VERSION ""

NS_ :

BS_:

BU_: BCM VSP STRG MA EPS AV AVM AIRBAG IPDMer BRAKE ABS VCM

BO_ 3221225472 VECTOR__INDEPENDENT_SIG_MSG: 0 Vector__XXX
 SG_ Unknown_176_4 : 32|8@1+ (1,0) [0|0] "" Vector__XXX
 SG_ NewSignal_0024 : 32|8@1+ (1,0) [0|0] "" Vector__XXX
 SG_ Unknown_215_6 : 0|8@1+ (1,0) [0|0] "" Vector__XXX
 SG_ NewSignal_0047 : 0|8@1+ (1,0) [0|0] "" Vector__XXX
 SG_ BCM_RearRightDoorOpene111d : 1|1@1+ (1,0) [0|0] "" Vector__XXX
 SG_ NewSignal_0089 : 9|1@1+ (1,0) [0|0] "" Vector__XXX
 SG_ Unknown_55A_0 : 0|8@1+ (1,0) [0|0] "" Vector__XXX
 SG_ RawTemperature2 : 55|16@0+ (1,0) [0|0] "" Vector__XXX
 SG_ GIDStoClusterMaybe : 8|8@1+ (1,0) [0|0] "" Vector__XXX
 SG_ InverterVehicleSpeedSignal : 0|8@1+ (1,0) [0|0] "" Vector__XXX
 SG_ MotorVoltageSignal : 8|8@1+ (1,0) [0|0] "" Vector__XXX
 SG_ InverterVehicleSpeedSignal2 : 16|8@1+ (1,0) [0|0] "" Vector__XXX
 SG_ MotorVoltageSignal2 : 24|8@1+ (1,0) [0|0] "" Vector__XXX
 SG_ Unknown_551_5 : 40|8@1+ (1,0) [0|0] "" Vector__XXX
 SG_ Unknown_50A_0 : 0|8@1+ (1,0) [0|0] "" Vector__XXX
 SG_ Unknown_50A_1 : 8|8@1+ (1,0) [0|0] "" Vector__XXX
 SG_ Unknown_50D_2 : 16|8@1+ (1,0) [0|0] "" Vector__XXX
 SG_ Unknown_50D_5 : 40|8@1+ (1,0) [0|0] "" Vector__XXX
 SG_ Unknown_5B3_2 : 16|8@1+ (1,0) [0|0] "" Vector__XXX
 SG_ Unknown_5B3_3 : 24|8@1+ (1,0) [0|0] "" Vector__XXX
 SG_ Unknown_5B3_6 : 48|3@1+ (1,0) [0|0] "" Vector__XXX
 SG_ Unknown_510_1 : 8|8@1+ (1,0) [0|0] "" Vector__XXX
 SG_ Unknown_245_1 : 8|4@1+ (1,0) [0|0] "" Vector__XXX

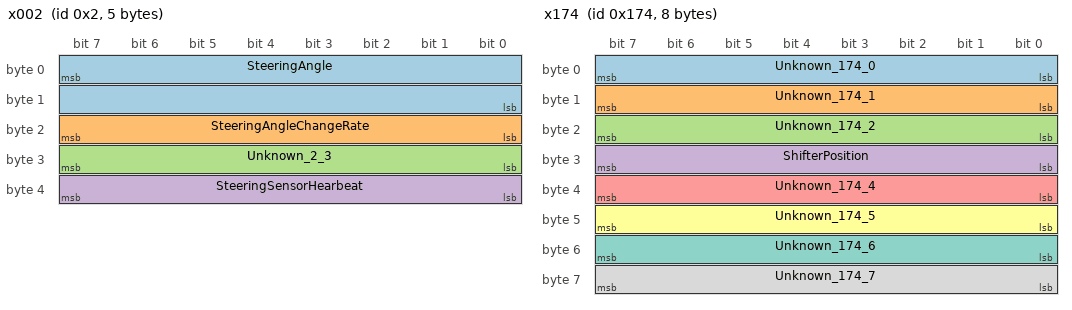
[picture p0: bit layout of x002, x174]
BO_ 2 x002: 5 STRG
 SG_ SteeringAngle : 7|16@0+ (1,0) [0|65535] "ddeg" Vector__XXX
 SG_ SteeringAngleChangeRate : 23|8@0+ (1,0) [0|255] "" Vector__XXX
 SG_ Unknown_2_3 : 31|8@0+ (1,0) [0|0] "" Vector__XXX
 SG_ SteeringSensorHearbeat : 39|8@0+ (1,0) [0|0] "" Vector__XXX

BO_ 42 x02A: 3 Vector__XXX
 SG_ Unknown_2A_0 : 0|8@1+ (1,0) [0|0] "" Vector__XXX
 SG_ Unknown_2A_1 : 8|8@1+ (1,0) [0|0] "" Vector__XXX
 SG_ Unknown_2A_2 : 16|8@1+ (1,0) [0|0] "" Vector__XXX

BO_ 304 x130: 3 ABS
 SG_ Unknown_130_0 : 0|8@1+ (1,0) [0|0] "" Vector__XXX
 SG_ BitmaskABS : 8|8@1+ (1,0) [0|0] "" Vector__XXX
 SG_ Unknown_130_1 : 16|8@1+ (1,0) [0|0] "" Vector__XXX

BO_ 372 x174: 8 VCM
 SG_ Unknown_174_0 : 0|8@1+ (1,0) [0|0] "" Vector__XXX
 SG_ Unknown_174_1 : 8|8@1+ (1,0) [0|0] "" Vector__XXX
 SG_ Unknown_174_2 : 16|8@1+ (1,0) [0|0] "" Vector__XXX
 SG_ ShifterPosition : 24|8@1+ (1,0) [0|0] "" Vector__XXX
 SG_ Unknown_174_4 : 32|8@1+ (1,0) [0|0] "" Vector__XXX
 SG_ Unknown_174_5 : 40|8@1+ (1,0) [0|0] "" Vector__XXX
 SG_ Unknown_174_6 : 48|8@1+ (1,0) [0|0] "" Vector__XXX
 SG_ Unknown_174_7 : 56|8@1+ (1,0) [0|0] "" Vector__XXX

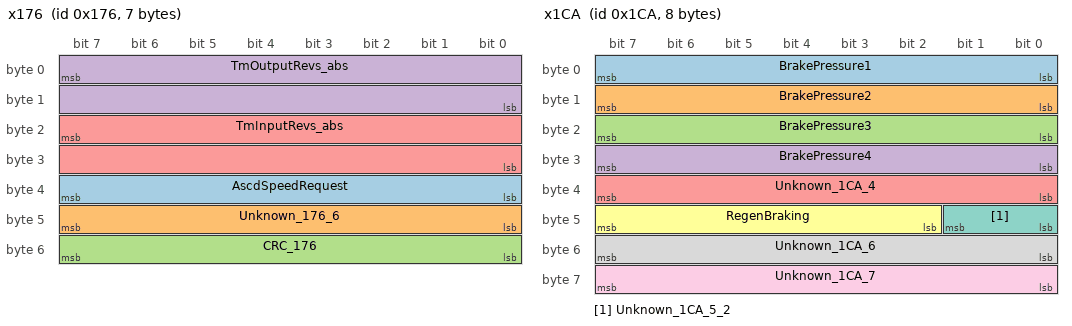
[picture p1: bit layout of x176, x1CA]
BO_ 374 x176: 7 VCM
 SG_ AscdSpeedRequest : 39|8@0+ (1,0) [0|250] "kmh" Vector__XXX
 SG_ Unknown_176_6 : 40|8@1+ (1,0) [0|0] "" Vector__XXX
 SG_ CRC_176 : 48|8@1+ (1,0) [0|0] "" Vector__XXX
 SG_ TmOutputRevs_abs : 7|16@0+ (1,0) [0|11000] "rpm" Vector__XXX
 SG_ TmInputRevs_abs : 23|16@0+ (1,0) [0|11000] "rpm" Vector__XXX

BO_ 384 x180_ECM_TorqueControl_RN1: 8 VCM
 SG_ Unknown_180_0 : 0|8@1+ (1,0) [0|0] "" Vector__XXX
 SG_ Unknown_180_1 : 8|8@1+ (1,0) [0|0] "" Vector__XXX
 SG_ MotorAmp : 23|12@0- (1,0) [0|0] "" Vector__XXX
 SG_ MotorAmpAlternative : 27|12@0- (1,0) [0|0] "" Vector__XXX
 SG_ ThrottlePosition : 40|8@1+ (0.5,0) [0|100] "%" Vector__XXX
 SG_ Unknown_180_5 : 48|8@1+ (1,0) [0|0] "" Vector__XXX
 SG_ Unknown_180_6 : 56|8@1+ (1,0) [0|0] "" Vector__XXX
 SG_ Unknown_180_7 : 0|8@1+ (1,0) [0|0] "" Vector__XXX

BO_ 458 x1CA: 8 BRAKE
 SG_ BrakePressure1 : 0|8@1+ (1,0) [0|0] "" Vector__XXX
 SG_ BrakePressure2 : 8|8@1+ (1,0) [0|0] "" Vector__XXX
 SG_ BrakePressure3 : 16|8@1+ (1,0) [0|0] "" Vector__XXX
 SG_ BrakePressure4 : 24|8@1+ (1,0) [0|0] "" Vector__XXX
 SG_ Unknown_1CA_4 : 32|8@1+ (1,0) [0|0] "" Vector__XXX
 SG_ RegenBraking : 42|6@1+ (1,0) [0|0] "" Vector__XXX
 SG_ Unknown_1CA_5_2 : 40|2@1+ (1,0) [0|0] "" Vector__XXX
 SG_ Unknown_1CA_6 : 48|8@1+ (1,0) [0|0] "" Vector__XXX
 SG_ Unknown_1CA_7 : 56|8@1+ (1,0) [0|0] "" Vector__XXX

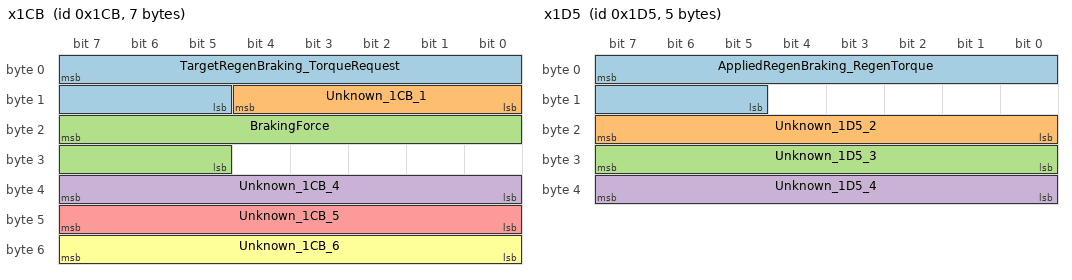
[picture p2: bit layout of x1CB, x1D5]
BO_ 459 x1CB: 7 Vector__XXX
 SG_ TargetRegenBraking_TorqueRequest : 7|11@0+ (1,0) [0|0] "Nm" Vector__XXX
 SG_ Unknown_1CB_1 : 8|5@1+ (1,0) [0|0] "" Vector__XXX
 SG_ BrakingForce : 23|11@0+ (1,0) [0|0] "N" Vector__XXX
 SG_ Unknown_1CB_4 : 32|8@1+ (1,0) [0|0] "" Vector__XXX
 SG_ Unknown_1CB_5 : 40|8@1+ (1,0) [0|0] "" Vector__XXX
 SG_ Unknown_1CB_6 : 48|8@1+ (1,0) [0|0] "" Vector__XXX

BO_ 469 x1D5: 5 VCM
 SG_ AppliedRegenBraking_RegenTorque : 7|11@0+ (1,0) [0|0] "Nm" Vector__XXX
 SG_ Unknown_1D5_2 : 16|8@1+ (1,0) [0|0] "" Vector__XXX
 SG_ Unknown_1D5_3 : 24|8@1+ (1,0) [0|0] "" Vector__XXX
 SG_ Unknown_1D5_4 : 32|8@1+ (1,0) [0|0] "" Vector__XXX

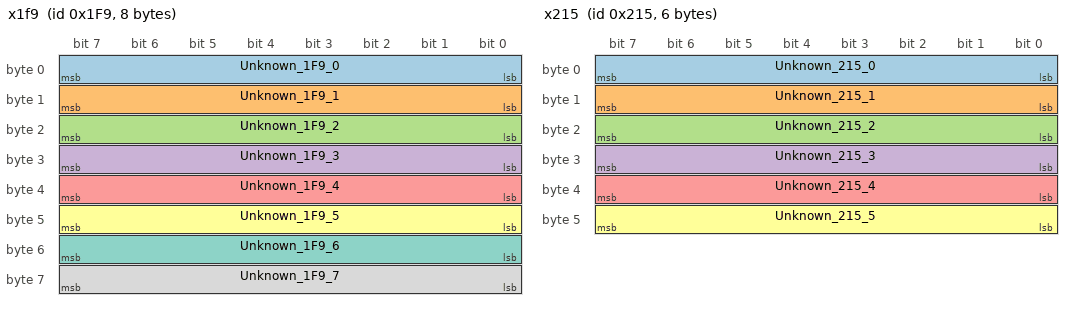
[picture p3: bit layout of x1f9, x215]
BO_ 505 x1f9: 8 Vector__XXX
 SG_ Unknown_1F9_0 : 0|8@1+ (1,0) [0|0] "" Vector__XXX
 SG_ Unknown_1F9_1 : 8|8@1+ (1,0) [0|0] "" Vector__XXX
 SG_ Unknown_1F9_2 : 16|8@1+ (1,0) [0|0] "" Vector__XXX
 SG_ Unknown_1F9_3 : 24|8@1+ (1,0) [0|0] "" Vector__XXX
 SG_ Unknown_1F9_4 : 32|8@1+ (1,0) [0|0] "" Vector__XXX
 SG_ Unknown_1F9_5 : 40|8@1+ (1,0) [0|0] "" Vector__XXX
 SG_ Unknown_1F9_6 : 48|8@1+ (1,0) [0|0] "" Vector__XXX
 SG_ Unknown_1F9_7 : 56|8@1+ (1,0) [0|0] "" Vector__XXX

BO_ 533 x215: 6 Vector__XXX
 SG_ Unknown_215_0 : 0|8@1+ (1,0) [0|0] "" Vector__XXX
 SG_ Unknown_215_1 : 8|8@1+ (1,0) [0|0] "" Vector__XXX
 SG_ Unknown_215_2 : 16|8@1+ (1,0) [0|0] "" Vector__XXX
 SG_ Unknown_215_3 : 24|8@1+ (1,0) [0|0] "" Vector__XXX
 SG_ Unknown_215_4 : 32|8@1+ (1,0) [0|0] "" Vector__XXX
 SG_ Unknown_215_5 : 40|8@1+ (1,0) [0|0] "" Vector__XXX

BO_ 534 x216: 2 Vector__XXX
 SG_ Unknown_216_0 : 0|8@1+ (1,0) [0|0] "" Vector__XXX
 SG_ Unknown_216_1 : 8|8@1+ (1,0) [0|0] "" Vector__XXX

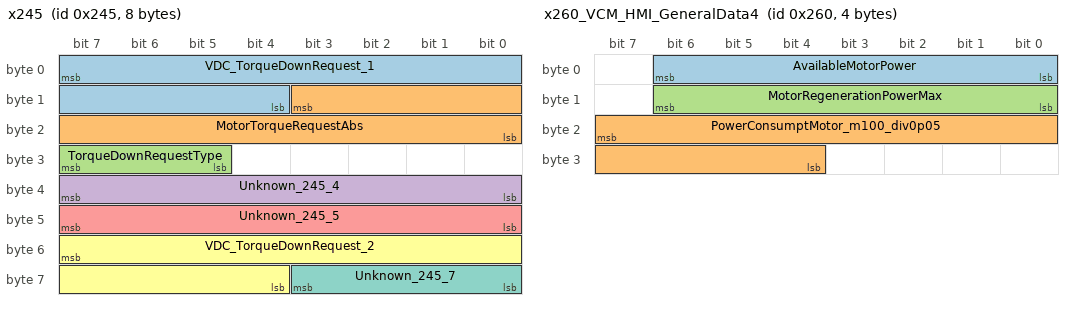
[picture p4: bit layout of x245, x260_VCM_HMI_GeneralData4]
BO_ 581 x245: 8 ABS
 SG_ VDC_TorqueDownRequest_1 : 7|12@0+ (2.5,0) [0|5115] "Nm" Vector__XXX
 SG_ MotorTorqueRequestAbs : 11|12@0+ (2.5,0) [0|5115] "Nm" Vector__XXX
 SG_ TorqueDownRequestType : 31|3@0+ (1,0) [0|0] "" Vector__XXX
 SG_ Unknown_245_4 : 32|8@1+ (1,0) [0|0] "" Vector__XXX
 SG_ Unknown_245_5 : 40|8@1+ (1,0) [0|0] "" Vector__XXX
 SG_ VDC_TorqueDownRequest_2 : 55|12@0+ (2.5,0) [0|5115] "Nm" Vector__XXX
 SG_ Unknown_245_7 : 56|4@1+ (1,0) [0|0] "" Vector__XXX

BO_ 608 x260_VCM_HMI_GeneralData4: 4 VCM
 SG_ AvailableMotorPower : 6|7@0+ (1,0) [0|90] "kW" Vector__XXX
 SG_ PowerConsumptMotor_m100_div0p05 : 23|12@0+ (0.05,-100) [-50|90] "kW" Vector__XXX
 SG_ MotorRegenerationPowerMax : 14|7@0+ (1,0) [0|50] "kW" Vector__XXX

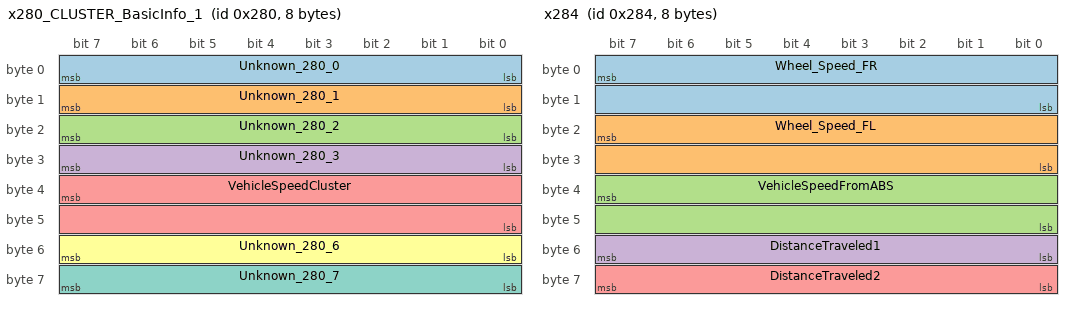
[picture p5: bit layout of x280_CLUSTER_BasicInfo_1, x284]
BO_ 640 x280_CLUSTER_BasicInfo_1: 8 MA
 SG_ Unknown_280_0 : 0|8@1+ (1,0) [0|0] "" Vector__XXX
 SG_ Unknown_280_1 : 8|8@1+ (1,0) [0|0] "" Vector__XXX
 SG_ Unknown_280_2 : 16|8@1+ (1,0) [0|0] "" Vector__XXX
 SG_ Unknown_280_3 : 24|8@1+ (1,0) [0|0] "" Vector__XXX
 SG_ VehicleSpeedCluster : 39|16@0+ (0.01,0) [0|0] "km/h" Vector__XXX
 SG_ Unknown_280_6 : 48|8@1+ (1,0) [0|0] "" Vector__XXX
 SG_ Unknown_280_7 : 56|8@1+ (1,0) [0|0] "" Vector__XXX

BO_ 644 x284: 8 ABS
 SG_ Wheel_Speed_FR : 7|16@0+ (0.005,0) [0|327] "km/h" Vector__XXX
 SG_ Wheel_Speed_FL : 23|16@0+ (0.005,0) [0|327] "km/h" Vector__XXX
 SG_ VehicleSpeedFromABS : 39|16@0+ (0.01,0) [0|0] "" Vector__XXX
 SG_ DistanceTraveled1 : 48|8@1+ (1,0) [0|0] "" Vector__XXX
 SG_ DistanceTraveled2 : 56|8@1+ (1,0) [0|0] "" Vector__XXX

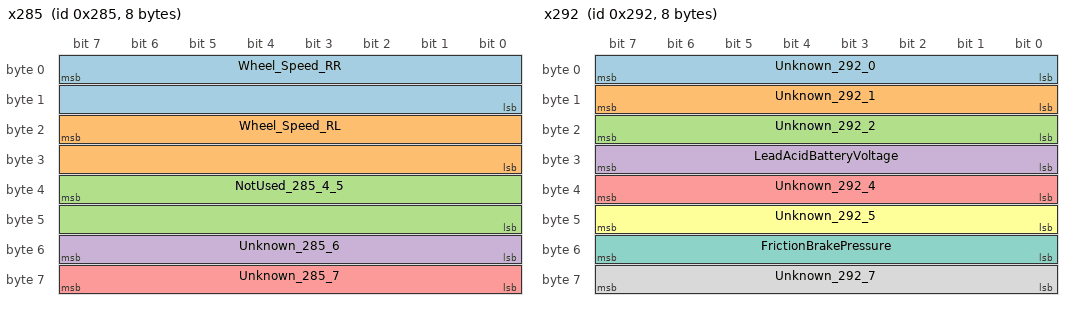
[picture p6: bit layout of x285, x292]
BO_ 645 x285: 8 ABS
 SG_ Wheel_Speed_RR : 7|16@0+ (0.005,0) [0|327] "km/h" Vector__XXX
 SG_ Wheel_Speed_RL : 23|16@0+ (0.005,0) [0|327] "km/h" Vector__XXX
 SG_ NotUsed_285_4_5 : 39|16@0+ (1,0) [0|0] "" Vector__XXX
 SG_ Unknown_285_6 : 48|8@1+ (1,0) [0|0] "" Vector__XXX
 SG_ Unknown_285_7 : 56|8@1+ (1,0) [0|0] "" Vector__XXX

BO_ 658 x292: 8 ABS
 SG_ Unknown_292_0 : 0|8@1+ (1,0) [0|0] "" Vector__XXX
 SG_ Unknown_292_1 : 8|8@1+ (1,0) [0|0] "" Vector__XXX
 SG_ Unknown_292_2 : 16|8@1+ (1,0) [0|0] "" Vector__XXX
 SG_ LeadAcidBatteryVoltage : 24|8@1+ (1,0) [0|150] "dV" Vector__XXX
 SG_ Unknown_292_4 : 32|8@1+ (1,0) [0|0] "" Vector__XXX
 SG_ Unknown_292_5 : 40|8@1+ (1,0) [0|0] "" Vector__XXX
 SG_ FrictionBrakePressure : 48|8@1+ (1,0) [0|255] "" Vector__XXX
 SG_ Unknown_292_7 : 56|8@1+ (1,0) [0|0] "" Vector__XXX

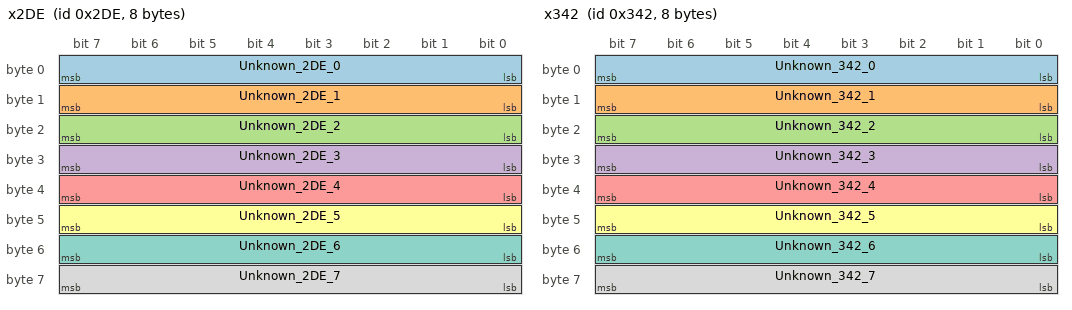
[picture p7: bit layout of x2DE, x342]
BO_ 734 x2DE: 8 Vector__XXX
 SG_ Unknown_2DE_0 : 0|8@1+ (1,0) [0|0] "" Vector__XXX
 SG_ Unknown_2DE_1 : 8|8@1+ (1,0) [0|0] "" Vector__XXX
 SG_ Unknown_2DE_2 : 16|8@1+ (1,0) [0|0] "" Vector__XXX
 SG_ Unknown_2DE_3 : 24|8@1+ (1,0) [0|0] "" Vector__XXX
 SG_ Unknown_2DE_4 : 32|8@1+ (1,0) [0|0] "" Vector__XXX
 SG_ Unknown_2DE_5 : 40|8@1+ (1,0) [0|0] "" Vector__XXX
 SG_ Unknown_2DE_6 : 48|8@1+ (1,0) [0|0] "" Vector__XXX
 SG_ Unknown_2DE_7 : 56|8@1+ (1,0) [0|0] "" Vector__XXX

BO_ 768 x300: 1 STRG
 SG_ SteeringWheelForce : 0|8@1+ (1,0) [0|255] "" Vector__XXX

BO_ 834 x342: 8 Vector__XXX
 SG_ Unknown_342_0 : 0|8@1+ (1,0) [0|0] "" Vector__XXX
 SG_ Unknown_342_1 : 8|8@1+ (1,0) [0|0] "" Vector__XXX
 SG_ Unknown_342_2 : 16|8@1+ (1,0) [0|0] "" Vector__XXX
 SG_ Unknown_342_3 : 24|8@1+ (1,0) [0|0] "" Vector__XXX
 SG_ Unknown_342_4 : 32|8@1+ (1,0) [0|0] "" Vector__XXX
 SG_ Unknown_342_5 : 40|8@1+ (1,0) [0|0] "" Vector__XXX
 SG_ Unknown_342_6 : 48|8@1+ (1,0) [0|0] "" Vector__XXX
 SG_ Unknown_342_7 : 56|8@1+ (1,0) [0|0] "" Vector__XXX

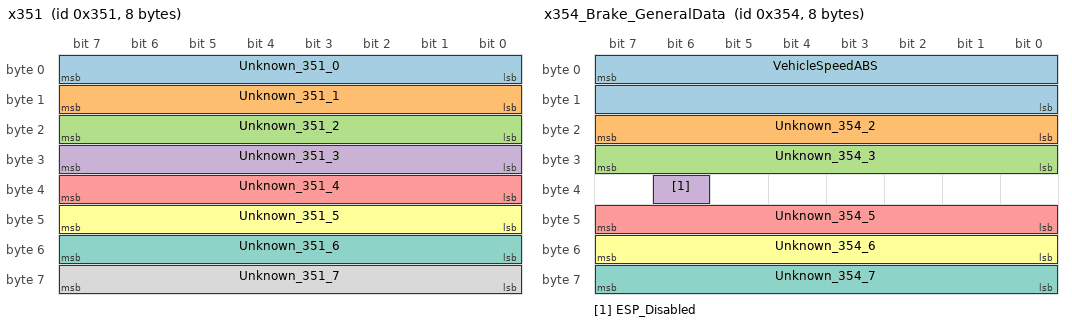
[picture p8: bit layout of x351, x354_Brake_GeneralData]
BO_ 849 x351: 8 Vector__XXX
 SG_ Unknown_351_0 : 0|8@1+ (1,0) [0|0] "" Vector__XXX
 SG_ Unknown_351_1 : 8|8@1+ (1,0) [0|0] "" Vector__XXX
 SG_ Unknown_351_2 : 16|8@1+ (1,0) [0|0] "" Vector__XXX
 SG_ Unknown_351_3 : 24|8@1+ (1,0) [0|0] "" Vector__XXX
 SG_ Unknown_351_4 : 32|8@1+ (1,0) [0|0] "" Vector__XXX
 SG_ Unknown_351_5 : 40|8@1+ (1,0) [0|0] "" Vector__XXX
 SG_ Unknown_351_6 : 48|8@1+ (1,0) [0|0] "" Vector__XXX
 SG_ Unknown_351_7 : 56|8@1+ (1,0) [0|0] "" Vector__XXX

BO_ 852 x354_Brake_GeneralData: 8 ABS
 SG_ VehicleSpeedABS : 7|16@0+ (1,0) [0|65535] "pulses" Vector__XXX
 SG_ Unknown_354_2 : 16|8@1+ (1,0) [0|0] "" Vector__XXX
 SG_ Unknown_354_3 : 24|8@1+ (1,0) [0|0] "" Vector__XXX
 SG_ ESP_Disabled : 38|1@1+ (1,0) [0|0] "" Vector__XXX
 SG_ Unknown_354_5 : 40|8@1+ (1,0) [0|0] "" Vector__XXX
 SG_ Unknown_354_6 : 48|8@1+ (1,0) [0|0] "" Vector__XXX
 SG_ Unknown_354_7 : 56|8@1+ (1,0) [0|0] "" Vector__XXX

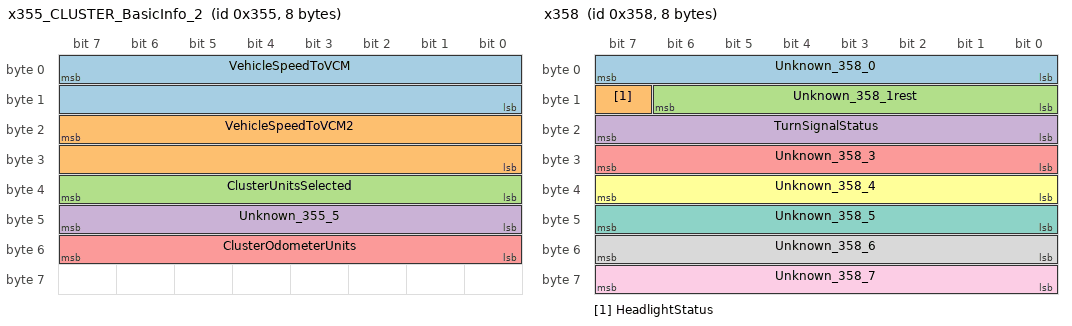
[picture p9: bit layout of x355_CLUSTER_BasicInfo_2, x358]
BO_ 853 x355_CLUSTER_BasicInfo_2: 8 MA
 SG_ VehicleSpeedToVCM : 7|16@0+ (0.01,0) [0|0] "" Vector__XXX
 SG_ VehicleSpeedToVCM2 : 23|16@0+ (0.01,0) [0|0] "" Vector__XXX
 SG_ ClusterUnitsSelected : 32|8@1+ (1,0) [0|0] "" Vector__XXX
 SG_ Unknown_355_5 : 40|8@1+ (1,0) [0|0] "" Vector__XXX
 SG_ ClusterOdometerUnits : 48|8@1+ (1,0) [0|0] "" Vector__XXX

BO_ 856 x358: 8 Vector__XXX
 SG_ Unknown_358_0 : 0|8@1+ (1,0) [0|0] "" Vector__XXX
 SG_ HeadlightStatus : 15|1@1+ (1,0) [0|0] "" Vector__XXX
 SG_ Unknown_358_1rest : 8|7@1+ (1,0) [0|0] "" Vector__XXX
 SG_ TurnSignalStatus : 16|8@1+ (1,0) [0|0] "" Vector__XXX
 SG_ Unknown_358_3 : 24|8@1+ (1,0) [0|0] "" Vector__XXX
 SG_ Unknown_358_4 : 32|8@1+ (1,0) [0|0] "" Vector__XXX
 SG_ Unknown_358_5 : 40|8@1+ (1,0) [0|0] "" Vector__XXX
 SG_ Unknown_358_6 : 48|8@1+ (1,0) [0|0] "" Vector__XXX
 SG_ Unknown_358_7 : 56|8@1+ (1,0) [0|0] "" Vector__XXX

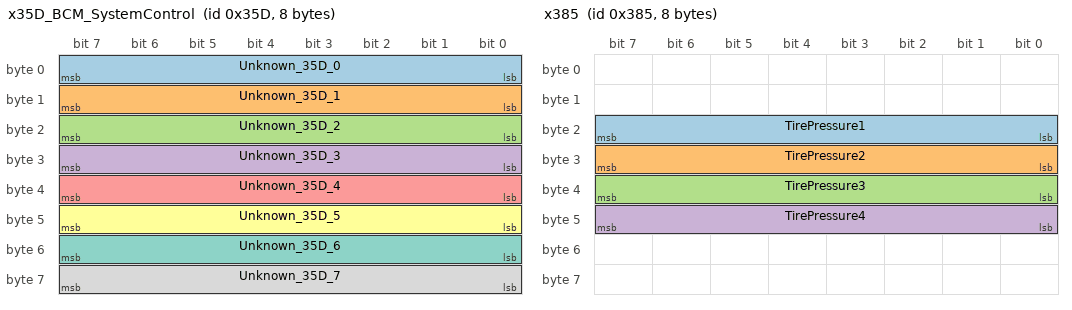
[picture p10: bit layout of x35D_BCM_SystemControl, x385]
BO_ 861 x35D_BCM_SystemControl: 8 BCM
 SG_ Unknown_35D_0 : 0|8@1+ (1,0) [0|0] "" Vector__XXX
 SG_ Unknown_35D_1 : 8|8@1+ (1,0) [0|0] "" Vector__XXX
 SG_ Unknown_35D_2 : 16|8@1+ (1,0) [0|0] "" Vector__XXX
 SG_ Unknown_35D_3 : 24|8@1+ (1,0) [0|0] "" Vector__XXX
 SG_ Unknown_35D_4 : 32|8@1+ (1,0) [0|0] "" Vector__XXX
 SG_ Unknown_35D_5 : 40|8@1+ (1,0) [0|0] "" Vector__XXX
 SG_ Unknown_35D_6 : 48|8@1+ (1,0) [0|0] "" Vector__XXX
 SG_ Unknown_35D_7 : 56|8@1+ (1,0) [0|0] "" Vector__XXX

BO_ 901 x385: 8 Vector__XXX
 SG_ TirePressure1 : 16|8@1+ (0.25,0) [0|0] "PSI" Vector__XXX
 SG_ TirePressure2 : 24|8@1+ (0.25,0) [0|0] "PSI" Vector__XXX
 SG_ TirePressure3 : 32|8@1+ (0.25,0) [0|0] "PSI" Vector__XXX
 SG_ TirePressure4 : 40|8@1+ (0.25,0) [0|0] "PSI" Vector__XXX

BO_ 1057 x421_ATCVT_to_MMI_RN1: 1 VCM
 SG_ DashShifterPosition : 7|5@0+ (1,0) [0|0] "" Vector__XXX

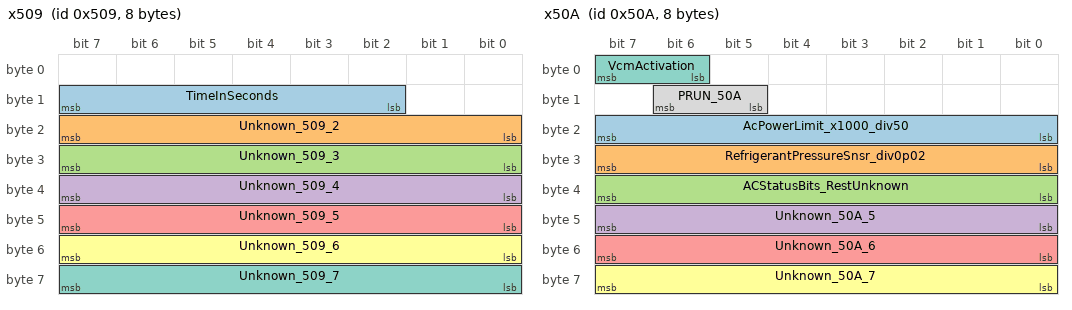
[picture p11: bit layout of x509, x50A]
BO_ 1289 x509: 8 Vector__XXX
 SG_ TimeInSeconds : 10|6@1+ (1,0) [0|59] "" Vector__XXX
 SG_ Unknown_509_2 : 16|8@1+ (1,0) [0|0] "" Vector__XXX
 SG_ Unknown_509_3 : 24|8@1+ (1,0) [0|0] "" Vector__XXX
 SG_ Unknown_509_4 : 32|8@1+ (1,0) [0|0] "" Vector__XXX
 SG_ Unknown_509_5 : 40|8@1+ (1,0) [0|0] "" Vector__XXX
 SG_ Unknown_509_6 : 48|8@1+ (1,0) [0|0] "" Vector__XXX
 SG_ Unknown_509_7 : 56|8@1+ (1,0) [0|0] "" Vector__XXX

BO_ 1290 x50A: 8 VCM
 SG_ AcPowerLimit_x1000_div50 : 23|8@0+ (1,0) [0|0] "" Vector__XXX
 SG_ RefrigerantPressureSnsr_div0p02 : 31|8@0+ (1,0) [0|0] "" Vector__XXX
 SG_ ACStatusBits_RestUnknown : 32|8@1+ (1,0) [0|0] "" Vector__XXX
 SG_ Unknown_50A_5 : 40|8@1+ (1,0) [0|0] "" Vector__XXX
 SG_ Unknown_50A_6 : 48|8@1+ (1,0) [0|0] "" Vector__XXX
 SG_ Unknown_50A_7 : 56|8@1+ (1,0) [0|0] "" Vector__XXX
 SG_ VcmActivation : 7|2@0+ (1,0) [0|2] "" Vector__XXX
 SG_ PRUN_50A : 14|2@0+ (1,0) [0|0] "" Vector__XXX

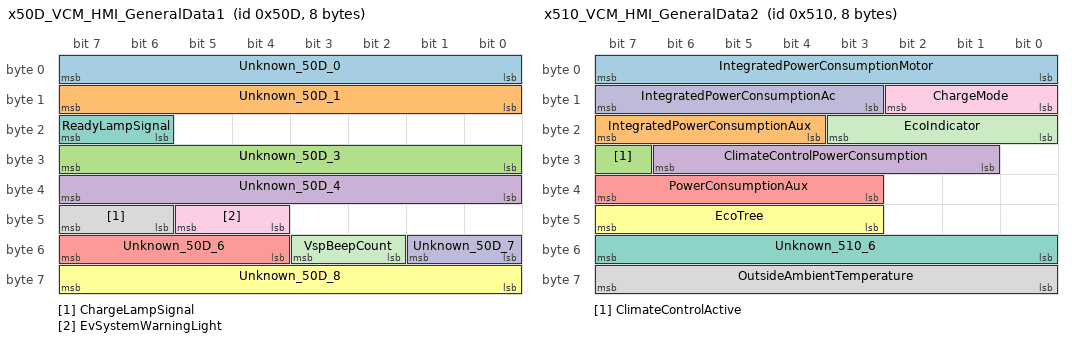
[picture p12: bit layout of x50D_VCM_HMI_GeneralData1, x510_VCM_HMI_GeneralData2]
BO_ 1293 x50D_VCM_HMI_GeneralData1: 8 VCM
 SG_ Unknown_50D_0 : 0|8@1+ (1,0) [0|0] "" Vector__XXX
 SG_ Unknown_50D_1 : 8|8@1+ (1,0) [0|0] "" Vector__XXX
 SG_ Unknown_50D_3 : 24|8@1+ (1,0) [0|0] "" Vector__XXX
 SG_ Unknown_50D_4 : 32|8@1+ (1,0) [0|0] "" Vector__XXX
 SG_ Unknown_50D_6 : 52|4@1+ (1,0) [0|0] "" Vector__XXX
 SG_ Unknown_50D_8 : 56|8@1+ (1,0) [0|0] "" Vector__XXX
 SG_ ReadyLampSignal : 23|2@0+ (1,0) [0|0] "" Vector__XXX
 SG_ ChargeLampSignal : 47|2@0+ (1,0) [0|0] "" Vector__XXX
 SG_ EvSystemWarningLight : 45|2@0+ (1,0) [0|0] "" Vector__XXX
 SG_ Unknown_50D_7 : 48|2@1+ (1,0) [0|0] "" Vector__XXX
 SG_ VspBeepCount : 50|2@1+ (1,0) [0|0] "" Vector__XXX

BO_ 1296 x510_VCM_HMI_GeneralData2: 8 VCM
 SG_ IntegratedPowerConsumptionMotor : 7|8@0+ (1,0) [0|255] "" Vector__XXX
 SG_ IntegratedPowerConsumptionAux : 23|4@0+ (1,0) [0|255] "" Vector__XXX
 SG_ ClimateControlActive : 31|1@1+ (1,0) [0|0] "" Vector__XXX
 SG_ ClimateControlPowerConsumption : 25|6@1+ (1,0) [0|0] "0.25kW" Vector__XXX
 SG_ PowerConsumptionAux : 39|5@0+ (1,0) [0|0] "" Vector__XXX
 SG_ EcoTree : 47|5@0+ (1,0) [0|0] "" Vector__XXX
 SG_ Unknown_510_6 : 48|8@1+ (1,0) [0|0] "" Vector__XXX
 SG_ OutsideAmbientTemperature : 56|8@1+ (0.5,-40) [-40|87.5] "degC" Vector__XXX
 SG_ ChargeMode : 10|3@0+ (1,0) [0|3] "" Vector__XXX
 SG_ IntegratedPowerConsumptionAc : 15|5@0+ (1,0) [0|0] "" Vector__XXX
 SG_ EcoIndicator : 19|4@0+ (1,0) [0|0] "" Vector__XXX

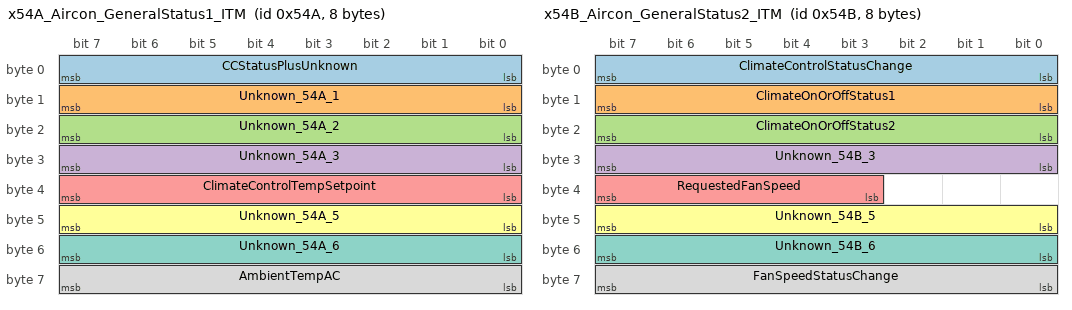
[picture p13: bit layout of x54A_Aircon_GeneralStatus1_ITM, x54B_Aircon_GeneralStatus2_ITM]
BO_ 1354 x54A_Aircon_GeneralStatus1_ITM: 8 VCM
 SG_ CCStatusPlusUnknown : 0|8@1+ (1,0) [0|0] "" Vector__XXX
 SG_ Unknown_54A_1 : 8|8@1+ (1,0) [0|0] "" Vector__XXX
 SG_ Unknown_54A_2 : 16|8@1+ (1,0) [0|0] "" Vector__XXX
 SG_ Unknown_54A_3 : 24|8@1+ (1,0) [0|0] "" Vector__XXX
 SG_ ClimateControlTempSetpoint : 32|8@1+ (1,0) [0|0] "" Vector__XXX
 SG_ Unknown_54A_5 : 40|8@1+ (1,0) [0|0] "" Vector__XXX
 SG_ Unknown_54A_6 : 48|8@1+ (1,0) [0|0] "" Vector__XXX
 SG_ AmbientTempAC : 56|8@1+ (1,0) [0|0] "" Vector__XXX

BO_ 1355 x54B_Aircon_GeneralStatus2_ITM: 8 VCM
 SG_ ClimateControlStatusChange : 0|8@1+ (1,0) [0|0] "" Vector__XXX
 SG_ ClimateOnOrOffStatus1 : 8|8@1+ (1,0) [0|0] "" Vector__XXX
 SG_ ClimateOnOrOffStatus2 : 16|8@1+ (1,0) [0|0] "" Vector__XXX
 SG_ Unknown_54B_3 : 24|8@1+ (1,0) [0|0] "" Vector__XXX
 SG_ RequestedFanSpeed : 35|5@1+ (1,0) [1|7] "speed" Vector__XXX
 SG_ Unknown_54B_5 : 40|8@1+ (1,0) [0|0] "" Vector__XXX
 SG_ Unknown_54B_6 : 48|8@1+ (1,0) [0|0] "" Vector__XXX
 SG_ FanSpeedStatusChange : 56|8@1+ (1,0) [0|0] "" Vector__XXX

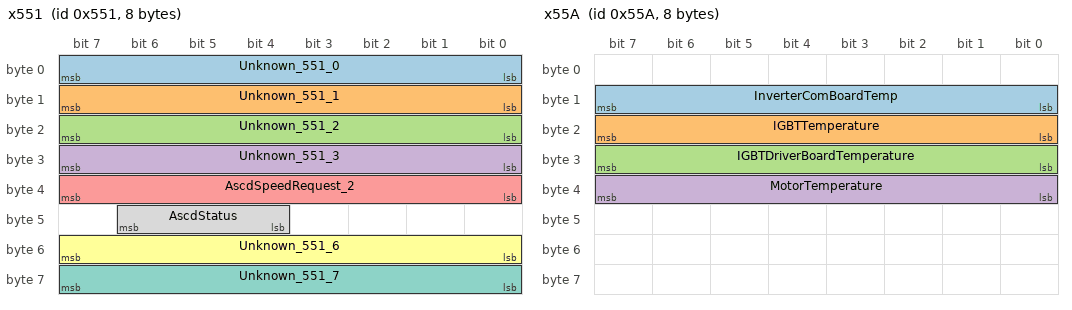
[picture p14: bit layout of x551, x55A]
BO_ 1361 x551: 8 VCM
 SG_ Unknown_551_0 : 0|8@1+ (1,0) [0|0] "" Vector__XXX
 SG_ Unknown_551_1 : 8|8@1+ (1,0) [0|0] "" Vector__XXX
 SG_ Unknown_551_2 : 16|8@1+ (1,0) [0|0] "" Vector__XXX
 SG_ Unknown_551_3 : 24|8@1+ (1,0) [0|0] "" Vector__XXX
 SG_ AscdSpeedRequest_2 : 39|8@0+ (1,0) [0|250] "kmh" Vector__XXX
 SG_ Unknown_551_6 : 48|8@1+ (1,0) [0|0] "" Vector__XXX
 SG_ Unknown_551_7 : 56|8@1+ (1,0) [0|0] "" Vector__XXX
 SG_ AscdStatus : 46|3@0+ (1,0) [0|0] "" Vector__XXX

BO_ 1370 x55A: 8 Vector__XXX
 SG_ InverterComBoardTemp : 8|8@1+ (1,0) [0|255] "dC*2" Vector__XXX
 SG_ IGBTTemperature : 16|8@1+ (1,0) [0|255] "dC*2" Vector__XXX
 SG_ IGBTDriverBoardTemperature : 24|8@1+ (1,0) [0|255] "dC*2" Vector__XXX
 SG_ MotorTemperature : 39|8@0+ (1,0) [0|255] "dC*2" Vector__XXX

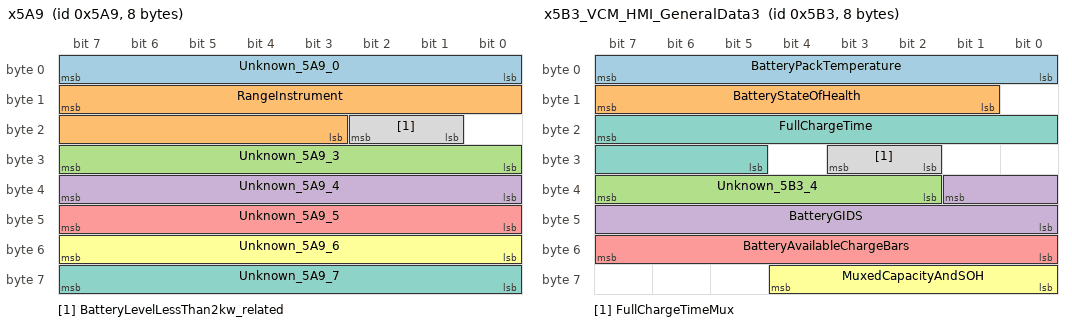
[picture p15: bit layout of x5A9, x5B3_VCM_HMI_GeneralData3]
BO_ 1449 x5A9: 8 VCM
 SG_ Unknown_5A9_0 : 0|8@1+ (1,0) [0|0] "" Vector__XXX
 SG_ RangeInstrument : 15|13@0+ (1,0) [0|0] "" Vector__XXX
 SG_ Unknown_5A9_3 : 24|8@1+ (1,0) [0|0] "" Vector__XXX
 SG_ Unknown_5A9_4 : 32|8@1+ (1,0) [0|0] "" Vector__XXX
 SG_ Unknown_5A9_5 : 40|8@1+ (1,0) [0|0] "" Vector__XXX
 SG_ Unknown_5A9_6 : 48|8@1+ (1,0) [0|0] "" Vector__XXX
 SG_ Unknown_5A9_7 : 56|8@1+ (1,0) [0|0] "" Vector__XXX
 SG_ BatteryLevelLessThan2kw_related : 18|2@0+ (1,0) [0|0] "" Vector__XXX

BO_ 1459 x5B3_VCM_HMI_GeneralData3: 8 VCM
 SG_ BatteryPackTemperature : 0|8@1+ (1,0) [0|255] "0.25C/bit" Vector__XXX
 SG_ BatteryStateOfHealth : 9|7@1+ (1,0) [0|127] "%" Vector__XXX
 SG_ Unknown_5B3_4 : 34|6@1+ (1,0) [0|0] "" Vector__XXX
 SG_ BatteryGIDS : 33|10@0+ (1,0) [0|511] "GIDs" Vector__XXX
 SG_ BatteryAvailableChargeBars : 55|8@0+ (1,0) [0|240] "-" Vector__XXX
 SG_ MuxedCapacityAndSOH : 60|5@0+ (1,0) [0|0] "" Vector__XXX
 SG_ FullChargeTime : 23|11@0+ (1,0) [0|0] "" Vector__XXX
 SG_ FullChargeTimeMux : 27|2@0+ (1,0) [0|0] "" Vector__XXX

BO_ 1472 x5C0_LBCMSG5: 8 VCM
 SG_ LB_Historical_Data_Swich_Flag M : 6|2@1+ (1,0) [0|3] "mux" Vector__XXX
 SG_ LB_Heating_Start_Send_Request : 5|1@1+ (1,0) [0|1] "status" Vector__XXX
 SG_ LB_Heating_Stop_Send_Request : 4|1@1+ (1,0) [0|1] "status" Vector__XXX
 SG_ Batt_Heater_Mail_Send_Request : 8|1@1+ (1,0) [0|1] "status" Vector__XXX
 SG_ LB_HEATEXIST : 32|1@1+ (1,0) [0|1] "status" Vector__XXX
 SG_ LB_NextWakeupTimeForBatterHeater : 48|5@1+ (1,0) [0|1800] "minutes" Vector__XXX
 SG_ LB_Diagnosis_Trouble_Code : 56|8@1+ (1,0) [0|255] "DTC" Vector__XXX
 SG_ LB_HistData_HighLow_Volt_Tim_MIN m3 : 0|4@1+ (1,0) [0|10] "times" Vector__XXX
 SG_ LB_HistData_HighLow_Volt_Tim_MAX m1 : 0|4@1+ (1,0) [0|10] "times" Vector__XXX
 SG_ LB_HistData_HighLow_Volt_Tim_AVG m2 : 0|4@1+ (1,0) [0|10] "times" Vector__XXX
 SG_ LB_HistData_Temp_WakeupPhase_MIN m3 : 9|7@1+ (1,-40) [-40|86] "degC" Vector__XXX
 SG_ LB_HistData_Temp_WakeupPhase_MAX m1 : 9|7@1+ (1,-40) [-40|86] "degC" Vector__XXX
 SG_ LB_HistData_Temp_WakeupPhase_AVG m2 : 9|7@1+ (1,-40) [-40|86] "degC" Vector__XXX
 SG_ LB_HistData_Temperature_MIN m3 : 17|7@1+ (1,-40) [-40|86] "degC" Vector__XXX
 SG_ LB_HistData_Temperature_MAX m1 : 17|7@1+ (1,-40) [-40|86] "degC" Vector__XXX
 SG_ LB_HistData_Temperature_AVG m2 : 17|7@1+ (1,-40) [-40|86] "degC" Vector__XXX
 SG_ LB_HistData_IntegratedCurrentMIN m3 : 24|8@1+ (0.6,0) [-76.2|76.2] "Ah" Vector__XXX
 SG_ LB_HistData_IntegratedCurrentMAX m1 : 24|8@1+ (0.6,0) [-76.2|76.2] "Ah" Vector__XXX
 SG_ LB_HistData_IntegratedCurrentAVG m2 : 24|8@1+ (0.6,0) [-76.2|76.2] "Ah" Vector__XXX
 SG_ LB_HistData_Degr_IntRes_CoeffMIN m3 : 33|7@1+ (1,0) [0|100] "%" Vector__XXX
 SG_ LB_HistData_Degr_IntRes_CoeffMAX m1 : 33|7@1+ (1,0) [0|100] "%" Vector__XXX
 SG_ LB_HistData_Degr_IntRes_CoeffAVG m2 : 33|7@1+ (1,0) [0|100] "%" Vector__XXX
 SG_ LB_HistData_Cell_Voltage_MIN m3 : 42|6@1+ (40,1900) [0|4380] "mV" Vector__XXX
 SG_ LB_HistData_Cell_Voltage_MAX m1 : 42|6@1+ (40,1900) [0|4380] "mV" Vector__XXX
 SG_ LB_HistData_Cell_Voltage_AVG m2 : 42|6@1+ (40,1900) [0|4380] "mV" Vector__XXX

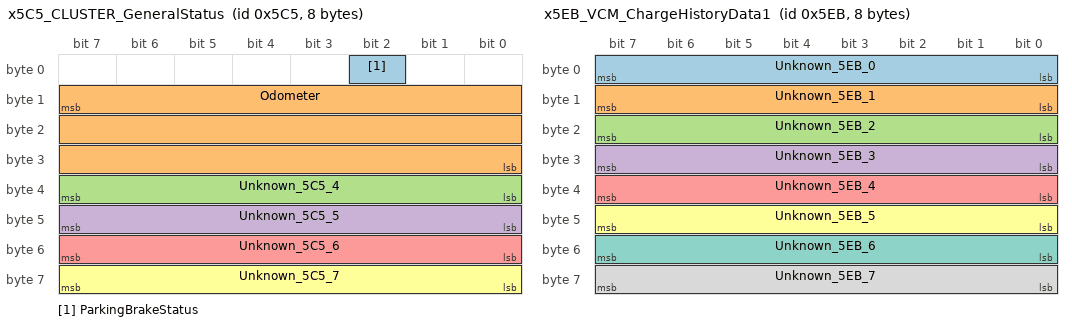
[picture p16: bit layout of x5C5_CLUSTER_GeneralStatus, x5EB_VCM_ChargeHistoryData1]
BO_ 1477 x5C5_CLUSTER_GeneralStatus: 8 MA
 SG_ ParkingBrakeStatus : 2|1@1+ (1,0) [0|0] "" Vector__XXX
 SG_ Odometer : 15|24@0+ (1,0) [0|16777215] "km / m" Vector__XXX
 SG_ Unknown_5C5_4 : 32|8@1+ (1,0) [0|0] "" Vector__XXX
 SG_ Unknown_5C5_5 : 40|8@1+ (1,0) [0|0] "" Vector__XXX
 SG_ Unknown_5C5_6 : 48|8@1+ (1,0) [0|0] "" Vector__XXX
 SG_ Unknown_5C5_7 : 56|8@1+ (1,0) [0|0] "" Vector__XXX

BO_ 1507 x5E3: 4 Vector__XXX
 SG_ Unknown_5E3_0 : 0|8@1+ (1,0) [0|0] "" Vector__XXX
 SG_ Unknown_5E3_1 : 8|8@1+ (1,0) [0|0] "" Vector__XXX
 SG_ Unknown_5E3_2 : 16|8@1+ (1,0) [0|0] "" Vector__XXX
 SG_ Unknown_5E3_3 : 24|8@1+ (1,0) [0|0] "" Vector__XXX

BO_ 1508 x5E4: 3 Vector__XXX
 SG_ Unknown_5E4_0 : 0|8@1+ (1,0) [0|0] "" Vector__XXX
 SG_ Unknown_5E4_1 : 8|8@1+ (1,0) [0|0] "" Vector__XXX
 SG_ Unknown_5E4_2 : 16|8@1+ (1,0) [0|0] "" Vector__XXX

BO_ 1515 x5EB_VCM_ChargeHistoryData1: 8 VCM
 SG_ Unknown_5EB_0 : 0|8@1+ (1,0) [0|0] "" Vector__XXX
 SG_ Unknown_5EB_1 : 8|8@1+ (1,0) [0|0] "" Vector__XXX
 SG_ Unknown_5EB_2 : 16|8@1+ (1,0) [0|0] "" Vector__XXX
 SG_ Unknown_5EB_3 : 24|8@1+ (1,0) [0|0] "" Vector__XXX
 SG_ Unknown_5EB_4 : 32|8@1+ (1,0) [0|0] "" Vector__XXX
 SG_ Unknown_5EB_5 : 40|8@1+ (1,0) [0|0] "" Vector__XXX
 SG_ Unknown_5EB_6 : 48|8@1+ (1,0) [0|0] "" Vector__XXX
 SG_ Unknown_5EB_7 : 56|8@1+ (1,0) [0|0] "" Vector__XXX

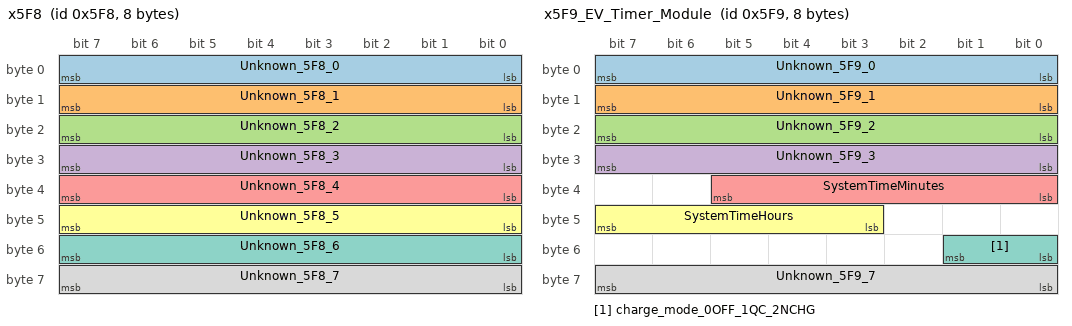
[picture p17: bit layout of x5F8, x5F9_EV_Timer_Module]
BO_ 1528 x5F8: 8 VCM
 SG_ Unknown_5F8_0 : 0|8@1+ (1,0) [0|0] "" Vector__XXX
 SG_ Unknown_5F8_1 : 8|8@1+ (1,0) [0|0] "" Vector__XXX
 SG_ Unknown_5F8_2 : 16|8@1+ (1,0) [0|0] "" Vector__XXX
 SG_ Unknown_5F8_3 : 24|8@1+ (1,0) [0|0] "" Vector__XXX
 SG_ Unknown_5F8_4 : 32|8@1+ (1,0) [0|0] "" Vector__XXX
 SG_ Unknown_5F8_5 : 40|8@1+ (1,0) [0|0] "" Vector__XXX
 SG_ Unknown_5F8_6 : 48|8@1+ (1,0) [0|0] "" Vector__XXX
 SG_ Unknown_5F8_7 : 56|8@1+ (1,0) [0|0] "" Vector__XXX

BO_ 1529 x5F9_EV_Timer_Module: 8 VCM
 SG_ Unknown_5F9_0 : 0|8@1+ (1,0) [0|0] "" Vector__XXX
 SG_ Unknown_5F9_1 : 8|8@1+ (1,0) [0|0] "" Vector__XXX
 SG_ Unknown_5F9_2 : 16|8@1+ (1,0) [0|0] "" Vector__XXX
 SG_ Unknown_5F9_3 : 24|8@1+ (1,0) [0|0] "" Vector__XXX
 SG_ SystemTimeMinutes : 32|6@1+ (1,0) [0|0] "" Vector__XXX
 SG_ SystemTimeHours : 43|5@1+ (1,0) [0|0] "" Vector__XXX
 SG_ charge_mode_0OFF_1QC_2NCHG : 49|2@0+ (1,0) [0|0] "" Vector__XXX
 SG_ Unknown_5F9_7 : 56|8@1+ (1,0) [0|0] "" Vector__XXX

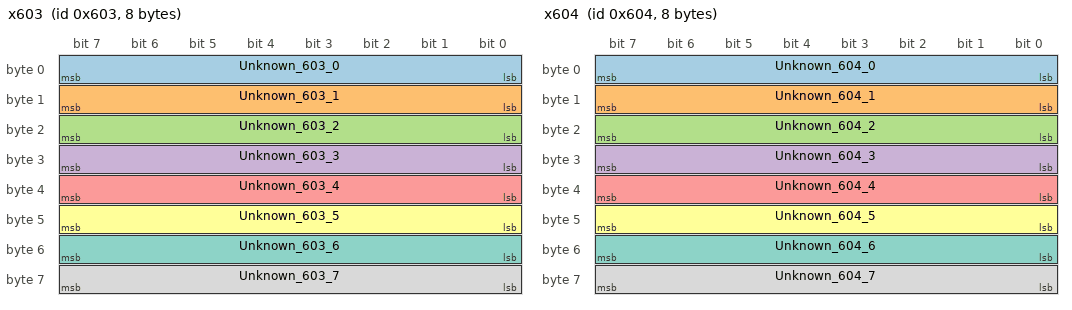
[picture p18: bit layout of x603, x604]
BO_ 1539 x603: 8 VCM
 SG_ Unknown_603_0 : 0|8@1+ (1,0) [0|0] "" Vector__XXX
 SG_ Unknown_603_1 : 8|8@1+ (1,0) [0|0] "" Vector__XXX
 SG_ Unknown_603_2 : 16|8@1+ (1,0) [0|0] "" Vector__XXX
 SG_ Unknown_603_3 : 24|8@1+ (1,0) [0|0] "" Vector__XXX
 SG_ Unknown_603_4 : 32|8@1+ (1,0) [0|0] "" Vector__XXX
 SG_ Unknown_603_5 : 40|8@1+ (1,0) [0|0] "" Vector__XXX
 SG_ Unknown_603_6 : 48|8@1+ (1,0) [0|0] "" Vector__XXX
 SG_ Unknown_603_7 : 56|8@1+ (1,0) [0|0] "" Vector__XXX

BO_ 1540 x604: 8 Vector__XXX
 SG_ Unknown_604_0 : 0|8@1+ (1,0) [0|0] "" Vector__XXX
 SG_ Unknown_604_1 : 8|8@1+ (1,0) [0|0] "" Vector__XXX
 SG_ Unknown_604_2 : 16|8@1+ (1,0) [0|0] "" Vector__XXX
 SG_ Unknown_604_3 : 24|8@1+ (1,0) [0|0] "" Vector__XXX
 SG_ Unknown_604_4 : 32|8@1+ (1,0) [0|0] "" Vector__XXX
 SG_ Unknown_604_5 : 40|8@1+ (1,0) [0|0] "" Vector__XXX
 SG_ Unknown_604_6 : 48|8@1+ (1,0) [0|0] "" Vector__XXX
 SG_ Unknown_604_7 : 56|8@1+ (1,0) [0|0] "" Vector__XXX

BO_ 1549 x60D_BCM_GeneralStatus7: 8 BCM
 SG_ Unknown_60D_bit : 0|1@1+ (1,0) [0|0] "" Vector__XXX
 SG_ BCM_ParkingLights : 1|2@1+ (1,0) [0|0] "" Vector__XXX
 SG_ BCM_PassengerDoorOpen : 3|1@1+ (1,0) [0|1] "" Vector__XXX
 SG_ BCM_DriverDoorOpen : 4|1@1+ (1,0) [0|1] "" Vector__XXX
 SG_ BCM_RearLeftDoorOpen : 5|1@1+ (1,0) [0|1] "" Vector__XXX
 SG_ BCM_RearRightDoorOpen : 6|1@1+ (1,0) [0|1] "" Vector__XXX
 SG_ BCM_TrunkOpen : 7|1@1+ (1,0) [0|1] "" Vector__XXX
 SG_ BCM_FogLights : 8|1@1+ (1,0) [0|1] "" Vector__XXX
 SG_ BCM_VehicleState : 9|2@1+ (1,0) [0|3] "Enumeration" Vector__XXX
 SG_ BCM_MainBeam : 11|1@1+ (1,0) [0|1] "" Vector__XXX
 SG_ Unknown_Bit_1_4 : 12|1@1+ (1,0) [0|1] "" Vector__XXX
 SG_ BCM_LeftTurnSignalFeedback : 13|1@1+ (1,0) [0|1] "On/Off" Vector__XXX
 SG_ BCM_RightTurnSignalFeedback : 14|1@1+ (1,0) [0|1] "On/Off" Vector__XXX
 SG_ BCM_HighBeamLights : 15|1@1+ (1,0) [0|1] "" Vector__XXX
 SG_ BCM_LeftTurnSignalCommand : 22|1@1+ (1,0) [0|1] "On/Off" Vector__XXX
 SG_ Unknown_60D_3 : 24|8@1+ (1,0) [0|0] "" Vector__XXX
 SG_ Unknown_60D_4 : 32|8@1+ (1,0) [0|0] "" Vector__XXX
 SG_ Unknown_60D_5 : 40|8@1+ (1,0) [0|0] "" Vector__XXX
 SG_ Unknown_60D_6 : 48|8@1+ (1,0) [0|0] "" Vector__XXX
 SG_ Unknown_60D_7 : 56|8@1+ (1,0) [0|0] "" Vector__XXX
 SG_ BCM_RightTurnSignalCommand : 21|1@1+ (1,0) [0|1] "On/Off" Vector__XXX
 SG_ BCM_DoorLockStatus_DriverDoor : 20|1@1+ (1,0) [0|1] "" Vector__XXX
 SG_ BCM_DoorLockStatus_OtherDoors : 19|1@1+ (1,0) [0|1] "" Vector__XXX

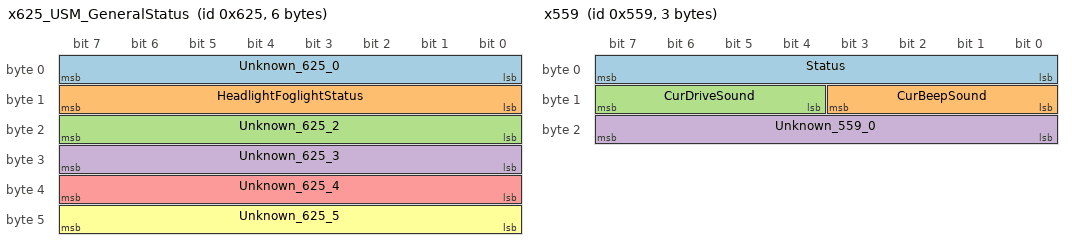
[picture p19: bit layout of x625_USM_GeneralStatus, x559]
BO_ 1573 x625_USM_GeneralStatus: 6 BCM
 SG_ Unknown_625_0 : 0|8@1+ (1,0) [0|0] "" Vector__XXX
 SG_ HeadlightFoglightStatus : 8|8@1+ (1,0) [0|0] "" Vector__XXX
 SG_ Unknown_625_2 : 16|8@1+ (1,0) [0|0] "" Vector__XXX
 SG_ Unknown_625_3 : 24|8@1+ (1,0) [0|0] "" Vector__XXX
 SG_ Unknown_625_4 : 32|8@1+ (1,0) [0|0] "" Vector__XXX
 SG_ Unknown_625_5 : 40|8@1+ (1,0) [0|0] "" Vector__XXX

BO_ 1666 x682: 8 Vector__XXX

BO_ 1676 x68C: 8 Vector__XXX

BO_ 1782 x6f6: 3 Vector__XXX
 SG_ Unknown_6F6_0 : 0|8@1+ (1,0) [0|0] "" Vector__XXX
 SG_ Unknown_6F6_1 : 8|8@1+ (1,0) [0|0] "" Vector__XXX
 SG_ Unknown_6F6_2 : 16|8@1+ (1,0) [0|0] "" Vector__XXX

BO_ 1542 x606: 1 VSP
 SG_ Wakeup : 0|8@1+ (1,0) [0|0] "" Vector__XXX

BO_ 1369 x559: 3 VSP
 SG_ Status : 0|8@1+ (1,0) [0|0] "" Vector__XXX
 SG_ CurBeepSound : 8|4@1+ (1,0) [0|0] "" Vector__XXX
 SG_ CurDriveSound : 12|4@1+ (1,0) [0|0] "" Vector__XXX
 SG_ Unknown_559_0 : 16|8@1+ (1,0) [0|0] "" Vector__XXX

CM_ BU_ BCM "Body Control Module";
CM_ BU_ VSP "Approaching vehicle sound for pedestrians (VSP) control unit";
CM_ BU_ STRG "Steering angle sensor";
CM_ BU_ MA "Combination meter";
CM_ BU_ EPS "Electronic Power Steering control unit";
CM_ BU_ AV "AV control unit (Optional)";
CM_ BU_ AVM "Around view monitor control unit (Optional)";
CM_ BU_ AIRBAG "Air bag diagnosis sensor unit";
CM_ BU_ IPDMer "Intelligent Power Distribution Module Engine Room";
CM_ BU_ BRAKE "Electrically-driven intelligent brake unit";
CM_ BU_ ABS "ABS actuator and electric control unit";
CM_ BU_ VCM "Vehicle Control Module";
CM_ SG_ 3221225472 GIDStoClusterMaybe "Seems to *somewhat* follow GIDs";
CM_ SG_ 3221225472 InverterVehicleSpeedSignal "???scalar of 0.0725 seems to translate roughly to mph; absolute (always positive)";
CM_ SG_ 3221225472 MotorVoltageSignal "???might be motor volts instead of speed
Should this message be connected with the first?";
CM_ SG_ 3221225472 InverterVehicleSpeedSignal2 "???scalar of .0091 seems to translate roughly to mph; always positive";
CM_ SG_ 3221225472 MotorVoltageSignal2 "??might be motor volts instead of speed
Should this message be connected to the above?";
CM_ SG_ 3221225472 Unknown_50A_0 "04,84,85";
CM_ SG_ 3221225472 Unknown_50A_1 "02,13,33,40,42,53,72,73";
CM_ BO_ 2 "Steering angle sensor signal. Goes to AV unit, Brake, and ABS modules";
CM_ SG_ 2 SteeringAngle "Steering Angle LSB:MSB
Left is negative
Degrees = value/10 (3600 = 360.0deg)";
CM_ SG_ 2 Unknown_2_3 "07?";
CM_ SG_ 2 SteeringSensorHearbeat "Heartbeat or CRC, yet to be confirmed
Very active (00-ff)";
CM_ BO_ 42 "???";
CM_ SG_ 42 Unknown_2A_0 "Always 0?";
CM_ SG_ 42 Unknown_2A_1 "Always 0?";
CM_ SG_ 42 Unknown_2A_2 "Always 0?";
CM_ SG_ 304 BitmaskABS "Bit5 = 1 = Traction control off?";
CM_ BO_ 372 "Relayed from E-Shift on EV-CAN";
CM_ SG_ 372 ShifterPosition "AA:Park/Neutral BB:Drive 99:Reverse";
CM_ SG_ 372 Unknown_174_4 "00...0F";
CM_ BO_ 374 "Might be VCM relay of Inverter message of motor RPM?";
CM_ SG_ 374 AscdSpeedRequest "00";
CM_ SG_ 374 Unknown_176_6 "00";
CM_ SG_ 374 CRC_176 "00...0F";
CM_ BO_ 384 "VCM";
CM_ SG_ 384 MotorAmp "2's compliment; Tracks power when multiplied with 176.23 and divided by ~30 or 176.01 divided by ~3.6";
CM_ SG_ 384 MotorAmpAlternative "Very similar to 180:B2/3 expect is clipped and decays to zero during regen";
CM_ BO_ 458 "Brake Control Module
(Not present on MY2013)";
CM_ BO_ 459 "Brake Module";
CM_ SG_ 459 TargetRegenBraking_TorqueRequest "Appears to be target regen before getting qualified by charge level, etc.";
CM_ BO_ 505 "VCM?";
CM_ BO_ 533 "? Key system ?";
CM_ BO_ 534 "Related to proximity key? 
I saw these messages on CAR can when there shouldn't be activity but I was walking near the car.";
CM_ BO_ 581 "???";
CM_ SG_ 581 Unknown_245_4 "Just ramps and wraps";
CM_ BO_ 608 "Data for instrumentation cluster";
CM_ BO_ 640 "Instrumentation cluster output 
TODO:
This area might contain lots of signals, see the LAN.pdf";
CM_ SG_ 640 Unknown_280_0 "Some activity here even when car is off, might be related to other dash lights (like the red key light)";
CM_ SG_ 640 Unknown_280_1 "Some activity here even when car is off, might be related to other dash lights (like the red key light)
370Z had seatbelt status as byte 0 bit 0. Need to verify. Could probably sync video of startup and CAN log to get the various lights and bytes used";
CM_ SG_ 640 VehicleSpeedCluster ".0062 scalar seems to match mph";
CM_ BO_ 644 "ABS Module

Common with other Nissans such as 370Z";
CM_ SG_ 644 Wheel_Speed_FR "Front right wheel speed";
CM_ SG_ 644 Wheel_Speed_FL "Front left wheel speed";
CM_ SG_ 644 VehicleSpeedFromABS ".0245";
CM_ BO_ 645 "ABS Module

Common with other Nissans such as 370Z";
CM_ SG_ 645 NotUsed_285_4_5 "284 contains speed, this message left empty";
CM_ BO_ 658 "ABS Module

Common with other Nissans such as 370Z";
CM_ SG_ 658 LeadAcidBatteryVoltage "Example, 7F = 12.7V";
CM_ SG_ 658 FrictionBrakePressure "Measured to provide the same braking force as 55 regen motor amps (cc180.23) per tick";
CM_ BO_ 734 "???";
CM_ SG_ 734 Unknown_2DE_6 "03";
CM_ SG_ 734 Unknown_2DE_7 "CA";
CM_ BO_ 768 "Steering Angle Sensor, force applied";
CM_ SG_ 768 SteeringWheelForce "Steering force applied to wheel";
CM_ BO_ 834 "? Key system ?

370Z notes this is related to key fob info";
CM_ SG_ 834 Unknown_342_0 "Only saw once in a log about the time I left to go inside.  Maybe related to the \"key is leaving the car while on\" chirp?";
CM_ BO_ 849 "???";
CM_ BO_ 852 "ABS Module

Same as 370Z";
CM_ SG_ 852 ESP_Disabled "True when traction control disabled";
CM_ BO_ 853 "Instrument cluster to VCM (Length?)

On my 2012 this is a 7 byte message (2011 8 byte?) 2013 ? lenght? This database is for AZE0";
CM_ SG_ 853 ClusterUnitsSelected "Selected dash miles/eff units

0x00=km;0x20=mi";
CM_ SG_ 853 ClusterOdometerUnits "Dash odometer units

The odometer value on the bus is always in units appropriate for the car's intended market and is unaffected by the dash display preference (in d[4] bit 5).

0x60=miles;0x40=km";
CM_ BO_ 856 "Body Control Module";
CM_ SG_ 856 HeadlightStatus "1 = ON, changes with manual control or auto";
CM_ SG_ 856 TurnSignalStatus "See value table";
CM_ BO_ 861 "Body Control Module";
CM_ BO_ 901 "Tire Pressure Monitoring System";
CM_ SG_ 901 TirePressure1 "FL?";
CM_ SG_ 901 TirePressure2 "FR?";
CM_ SG_ 901 TirePressure3 "RL?";
CM_ SG_ 901 TirePressure4 "RR?";
CM_ BO_ 1057 "VCM relay from shifter on EV bus to Instrument panel and VSP. Does this exist on AZE0?";
CM_ SG_ 1057 DashShifterPosition "Controls PRNDE display on dash (investigate B mode?)

0x18 = Neutral
0x08 = Park
0x20 = Drive
0x10 = Reverse
0x38 = ECO ";
CM_ BO_ 1289 "???";
CM_ SG_ 1289 TimeInSeconds "0-59";
CM_ BO_ 1290 "VCM relay from A/C Auto Amp and AC Pressor Sensor (which is measured directly from VCM) Message is identical on EV CAN and CAR CAN (100ms)

AC compressor pressure goes directly into VCM, this value is only for Consult reference";
CM_ SG_ 1290 ACStatusBits_RestUnknown "00,80  BIT1 = Rear defrost on/off";
CM_ SG_ 1290 Unknown_50A_5 "a0";
CM_ SG_ 1290 Unknown_50A_6 "04 , Only present in 2013+ (otherwise frame stops at 6bytes)";
CM_ SG_ 1290 Unknown_50A_7 "00 , Only present in 2013+ (otherwise frame stops at 6bytes)";
CM_ SG_ 1293 VspBeepCount "Send non-zero values for 3 packets to trigger beep";
CM_ BO_ 1296 "VCM relay from A/C Auto Amp, to eyebrow display and A/V unit";
CM_ SG_ 1296 IntegratedPowerConsumptionAux "Increments roughly every second";
CM_ SG_ 1296 ClimateControlPowerConsumption "0.25kW per lsb";
CM_ SG_ 1296 OutsideAmbientTemperature "Identical to EV CAN msg 0x54C byte 6

This one has half-degree C resolution and seems to stay within a degree or two of the \"eyebrow\" temp display.";
CM_ BO_ 1354 "VCM relay from A/C Auto Amp to A/V unit for climate display (100ms)";
CM_ SG_ 1354 CCStatusPlusUnknown "12,3c- CC Off; a0,da- CC On";
CM_ SG_ 1354 Unknown_54A_1 "00 (80 in 2013+)";
CM_ SG_ 1354 Unknown_54A_2 "70";
CM_ SG_ 1354 Unknown_54A_3 "06,0a,0b,0f";
CM_ SG_ 1354 ClimateControlTempSetpoint "00,39,52,53,54 (MY2011,2012)";
CM_ SG_ 1354 Unknown_54A_5 "00";
CM_ SG_ 1354 Unknown_54A_6 "00";
CM_ SG_ 1354 AmbientTempAC "Appears to track ambient (+41)

0x83=90F;0x79=79F (90F & 79F read from dash);  also some low reads at poweron

4f,8c-90";
CM_ BO_ 1355 "VCM relay from A/C Auto Amp to A/V unit for climate display (100ms)";
CM_ SG_ 1355 ClimateControlStatusChange "Used to alert A/V unit that CC being toggled on or off by the user so the A/V can display the fan and CC settings on the display 00 no change, 01 change";
CM_ SG_ 1355 ClimateOnOrOffStatus1 "08 off, 78 on";
CM_ SG_ 1355 ClimateOnOrOffStatus2 "80 off, 88 on";
CM_ SG_ 1355 Unknown_54B_3 "00,08,09,10,12 observed, mostly 09 while CC on";
CM_ SG_ 1355 RequestedFanSpeed "1<->7 ";
CM_ SG_ 1355 FanSpeedStatusChange "Used to alert A/V unit that fan speed is being changed by the user so the A/V can display the fan and CC settings on the display 00 no change, 01 change";
CM_ SG_ 1361 AscdSpeedRequest_2 "80 with CC on , 00 off";
CM_ BO_ 1370 "Inverter (100ms)";
CM_ SG_ 1370 IGBTDriverBoardTemperature "Temperature only active during drive (IGBT driver board?)";
CM_ BO_ 1449 "Vehicle Control Module (100ms)

This message appeared after recall/update in March 2012. Probably VCM to TCU for carwings (engineering data)";
CM_ SG_ 1449 RangeInstrument "OVMS sets nl_range from this with the following formula

nl_range = d[1] << 4 | d[2] >> 4;
m_range_instrument->SetValue(nl_range / 5, Kilometers);

TODO, set bitpos according to OVMS";
CM_ BO_ 1459 "VCM relayed and processed data to instrument cluster";
CM_ SG_ 1459 BatteryPackTemperature "Probably used to drive temp bars on cluster";
CM_ SG_ 1459 BatteryStateOfHealth "Confirmed to contain State-Of-Health (SOH)";
CM_ SG_ 1459 BatteryGIDS "A GID is a measure used by the LEAF internally, and seems to be roughly equivalent to about 80 watt-hours. A new 24kWh LEAF will charge up to about 271 GIDs on a 100% charge when the battery is new.";
CM_ SG_ 1459 BatteryAvailableChargeBars "0-240";
CM_ SG_ 1459 MuxedCapacityAndSOH "Possibly capacity bargraph when D0=FE; SOH otherwise. TODO: Add mux to this message after testing";
CM_ BO_ 1472 "Relayed LBC message from EV-CAN (500ms)";
CM_ SG_ 1472 LB_Historical_Data_Swich_Flag "Mux for historical data signals";
CM_ SG_ 1472 LB_Heating_Start_Send_Request "0->1 Heat start Mail send request";
CM_ SG_ 1472 LB_Heating_Stop_Send_Request "0->1 Heat stop Mail send request";
CM_ SG_ 1472 LB_HEATEXIST "Specifies if battery pack is equipped with heating elements";
CM_ SG_ 1472 LB_HistData_HighLow_Volt_Tim_MIN "LB_Historical_Data_High_or_Low_Voltage_Times";
CM_ SG_ 1472 LB_HistData_HighLow_Volt_Tim_MAX "LB_Historical_Data_High_or_Low_Voltage_Times";
CM_ SG_ 1472 LB_HistData_HighLow_Volt_Tim_AVG "LB_Historical_Data_High_or_Low_Voltage_Times";
CM_ SG_ 1472 LB_HistData_Temp_WakeupPhase_MIN "LB_Historical_Data_Temperature_Wakeup_Phase";
CM_ SG_ 1472 LB_HistData_Temp_WakeupPhase_MAX "LB_Historical_Data_Temperature_Wakeup_Phase";
CM_ SG_ 1472 LB_HistData_Temp_WakeupPhase_AVG "LB_Historical_Data_Temperature_Wakeup_Phase";
CM_ SG_ 1472 LB_HistData_Temperature_MAX "Affects cluster gauge for temperature?";
CM_ SG_ 1472 LB_HistData_IntegratedCurrentMIN "2S

LB_Historical_Data_Integrated_Current";
CM_ SG_ 1472 LB_HistData_IntegratedCurrentMAX "2S

LB_Historical_Data_Integrated_Current";
CM_ SG_ 1472 LB_HistData_IntegratedCurrentAVG "2S

LB_Historical_Data_Integrated_Current";
CM_ SG_ 1472 LB_HistData_Degr_IntRes_CoeffMIN "LB_Historical_Data_Degradation_Internal_Resistance_Coefficient ";
CM_ SG_ 1472 LB_HistData_Degr_IntRes_CoeffMAX "LB_Historical_Data_Degradation_Internal_Resistance_Coefficient ";
CM_ SG_ 1472 LB_HistData_Degr_IntRes_CoeffAVG "LB_Historical_Data_Degradation_Internal_Resistance_Coefficient ";
CM_ BO_ 1477 "Instrument cluster -> BCM / AV / VCM";
CM_ SG_ 1477 ParkingBrakeStatus "This is the parking brake (which is foot-operated on AZE0)";
CM_ SG_ 1477 Odometer "Odo is handled by the cluster display and is transmitted to body control module, AV, and VCM";
CM_ BO_ 1507 "???";
CM_ BO_ 1508 "???";
CM_ BO_ 1515 "Only active when driving
";
CM_ BO_ 1528 "???";
CM_ SG_ 1528 Unknown_5F8_0 "Increments once a minute?";
CM_ BO_ 1529 "???";
CM_ SG_ 1529 SystemTimeMinutes "Time:minute (0-59)";
CM_ SG_ 1529 SystemTimeHours "Time:hour (0-23)";
CM_ BO_ 1539 "Wake up message from VCM

Noticing this shows up on CARcan right after 68c shows up on EVCan.";
CM_ BO_ 1540 "???";
CM_ BO_ 1549 "Body control module

Most likely, not confirmed

Funfact, In the 370z there are lock, door, and headlight statuses in this message";
CM_ SG_ 1549 BCM_ParkingLights "3 - dim lights 
2 - parking lights (first mode on the control)";
CM_ SG_ 1549 BCM_FogLights "1 - fog lights (together with 1-2 bits of the byte #0) TODO: Verify message";
CM_ SG_ 1549 BCM_VehicleState "0 - OFF, 
1 - power button is pressed once without brakes.
2 - is sent during the startup sequence before 1 and 3 for 2 seconds
3 - either car is in Ready On mode or the power button is pressed the second time after the mode '1'";
CM_ SG_ 1549 BCM_LeftTurnSignalFeedback "Not the control, but the actual light";
CM_ SG_ 1549 BCM_RightTurnSignalFeedback "Not the control, but the actual light";
CM_ SG_ 1549 BCM_HighBeamLights "1 - high beam lights (together with 1-2 bits of the byte #0) TODO: Verify this";
CM_ SG_ 1549 BCM_LeftTurnSignalCommand "Control Value";
CM_ SG_ 1549 BCM_RightTurnSignalCommand "Control Value";
CM_ BO_ 1573 "USM";
CM_ SG_ 1573 HeadlightFoglightStatus "00: Lights off 60: Headlights on 40: Parking Lights on 68:Headlights and fog lights";
CM_ BO_ 1666 "Wake up message

In 370z this \"Sleep wakeup\" perhaps modules on the car can use this to wake up VCM";
CM_ BO_ 1676 "Wake up message

68C on EVcan is TCU (Carwings) so it might be a relay from VCM or a log mixup";
CM_ BO_ 1782 "???";
CM_ BO_ 1542 "Wake up message";
CM_ BO_ 1369 "VSP Information";
CM_ SG_ 1369 Status "Most common value is 0x48 when receiving CAN packets or 0x68 when not receiving CAN packets.";
CM_ SG_ 1369 CurBeepSound "Active when playing beeps";
CM_ SG_ 1369 CurDriveSound "Active when playing the start-up or one of the drive sounds";
CM_ SG_ 1369 Unknown_559_0 "Seems always to have the value 0x10";
VAL_ 372 ShifterPosition 170 "Park/Neutral" 187 "Drive" 153 "Reverse" ;
VAL_ 853 ClusterUnitsSelected 0 "Kilometers" 32 "Miles" ;
VAL_ 853 ClusterOdometerUnits 64 "Kilometers" 96 "Miles" ;
VAL_ 856 TurnSignalStatus 0 "BothOff" 4 "Left Signal ON" 8 "Right Signal ON" 12 "Both Signals ON (Hazards)" ;
VAL_ 1057 DashShifterPosition 1 "Park" 2 "Reverse" 3 "Neutral" 4 "Drive" 5 "ECO" ;
VAL_ 1290 VcmActivation 0 "NON" 2 "READY" ;
VAL_ 1293 VspBeepCount 0 "No Beeps" 1 "One Beep" 2 "Two Beeps" 3 "Three Beeps" ;
VAL_ 1296 ClimateControlActive 0 "CC Off" 1 "CC On" ;
VAL_ 1296 ChargeMode 1 "110V" 2 "220V" 3 "QC" 0 "OFF" ;
VAL_ 1355 ClimateControlStatusChange 0 "No change" 1 "Changed" ;
VAL_ 1355 FanSpeedStatusChange 0 "No change" 1 "Change" ;
VAL_ 1472 LB_Historical_Data_Swich_Flag 0 "Not Calculated" 1 "Maximum Data" 2 "Average Data" 3 "Minimum Data" ;
VAL_ 1472 Batt_Heater_Mail_Send_Request 0 "No request" 1 "Mail send request" ;
VAL_ 1477 ParkingBrakeStatus 0 "Parking brake off" 1 "Parking brake on" ;
VAL_ 1549 BCM_VehicleState 0 "Vehicle OFF" 1 "Power button pressed once without brakes" 2 "Booting up. 2 during the startup sequence before state1 and state3 for 2 seconds" 3 "Vehicle ON (Ready or ACC)" ;
VAL_ 1369 CurBeepSound 0 "No Beep playing" 4 "One Beep playing" 8 "Two Beeps playing" 12 "Three Beeps playing" ;
VAL_ 1369 CurDriveSound 0 "No sound playing" 2 "Startup sound playing" 4 "Drive Start sound playing" 8 "Drive VSP sound playing" 12 "Reverse sound playing" ;
